# STM32F765BGT6 register map
File version: 1.0
Registers are 32-bit, access not given, reset 0x0 unless marked. A register's access mark holds for its fields unless they carry their own. Offsets are from the block's base; [hi:lo] are bit positions; {n}, {i} and the like mark numbered series.

## WWDG
Base 0x40002C00
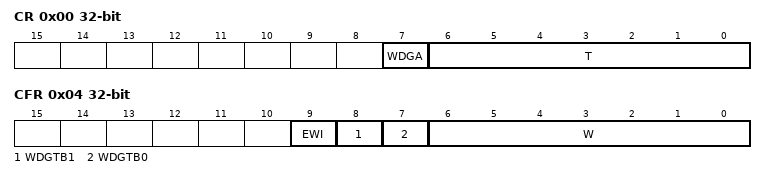
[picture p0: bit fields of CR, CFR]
0x00 CR
  [7] WDGA, [6:0] T
0x04 CFR
  [9] EWI, [8] WDGTB1, [7] WDGTB0, [6:0] W
0x08 SR
  [0] EWIF

## IWDG
Base 0x40003000
0x00 KR
  [15:0] KEY
0x04 PR
  [2:0] PR
0x08 RLR
  [11:0] RL
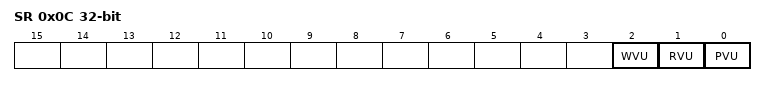
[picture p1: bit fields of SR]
0x0C SR
  [2] WVU, [1] RVU, [0] PVU
0x10 WINR
  [11:0] WIN

## CAN3
Base 0x40003400
Same registers: CAN1 0x40006400, CAN2 0x40006800
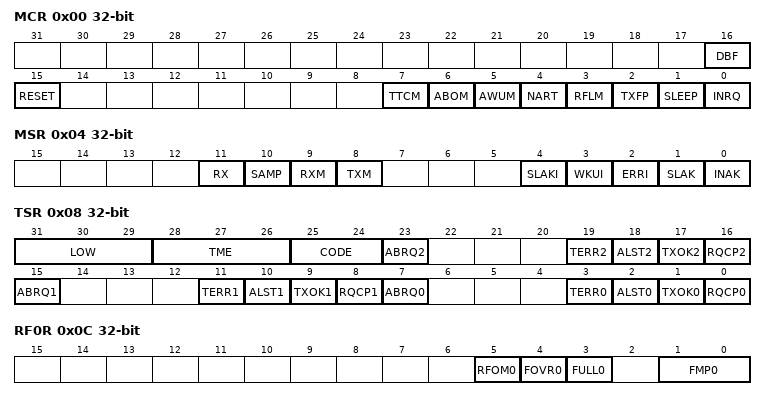
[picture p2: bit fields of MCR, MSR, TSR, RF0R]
0x00 MCR
  [16] DBF, [15] RESET, [7] TTCM, [6] ABOM, [5] AWUM, [4] NART, [3] RFLM, [2] TXFP, [1] SLEEP, [0] INRQ
0x04 MSR
  [11] RX, [10] SAMP, [9] RXM, [8] TXM, [4] SLAKI, [3] WKUI, [2] ERRI, [1] SLAK, [0] INAK
0x08 TSR
  [31:29] LOW, [28:26] TME, [25:24] CODE, [23] ABRQ2, [19] TERR2, [18] ALST2, [17] TXOK2, [16] RQCP2, [15] ABRQ1, [11] TERR1, [10] ALST1, [9] TXOK1, [8] RQCP1, [7] ABRQ0, [3] TERR0, [2] ALST0, [1] TXOK0, [0] RQCP0
0x0C RF0R
  [5] RFOM0, [4] FOVR0, [3] FULL0, [1:0] FMP0
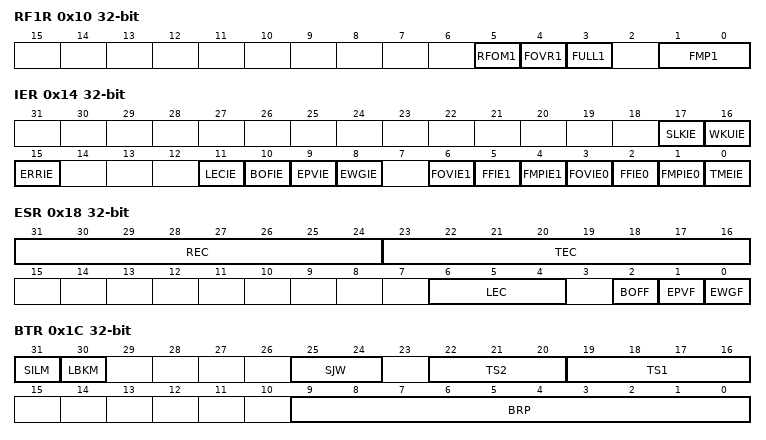
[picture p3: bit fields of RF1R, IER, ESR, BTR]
0x10 RF1R
  [5] RFOM1, [4] FOVR1, [3] FULL1, [1:0] FMP1
0x14 IER
  [17] SLKIE, [16] WKUIE, [15] ERRIE, [11] LECIE, [10] BOFIE, [9] EPVIE, [8] EWGIE, [6] FOVIE1, [5] FFIE1, [4] FMPIE1, [3] FOVIE0, [2] FFIE0, [1] FMPIE0, [0] TMEIE
0x18 ESR
  [31:24] REC, [23:16] TEC, [6:4] LEC, [2] BOFF, [1] EPVF, [0] EWGF
0x1C BTR
  [31] SILM, [30] LBKM, [25:24] SJW, [22:20] TS2, [19:16] TS1, [9:0] BRP
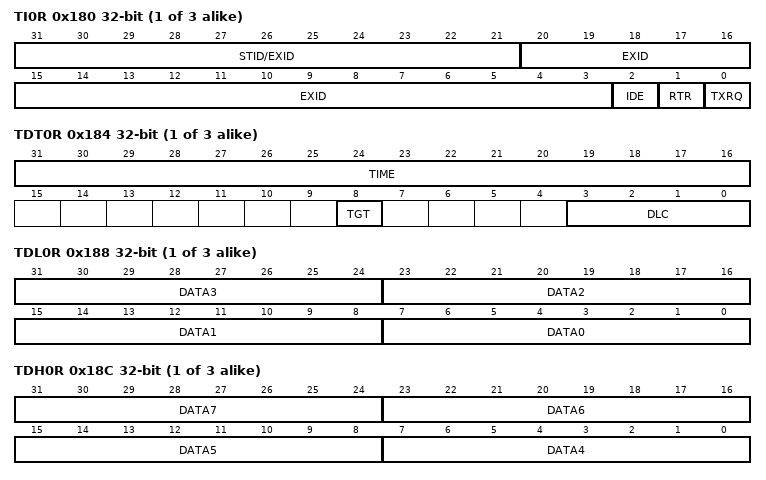
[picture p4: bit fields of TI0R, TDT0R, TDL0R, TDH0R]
{0x180+0x10*i} TI{i}R (i=0..2)
  [31:21] STID/EXID, [20:3] EXID, [2] IDE, [1] RTR, [0] TXRQ
{0x184+0x10*i} TDT{i}R (i=0..2)
  [31:16] TIME, [8] TGT, [3:0] DLC
{0x188+0x10*i} TDL{i}R (i=0..2)
  [8n+7:8n] DATA{n} (n=0..3)
{0x18C+0x10*i} TDH{i}R (i=0..2)
  [8n-25:8n-32] DATA{n} (n=4..7)
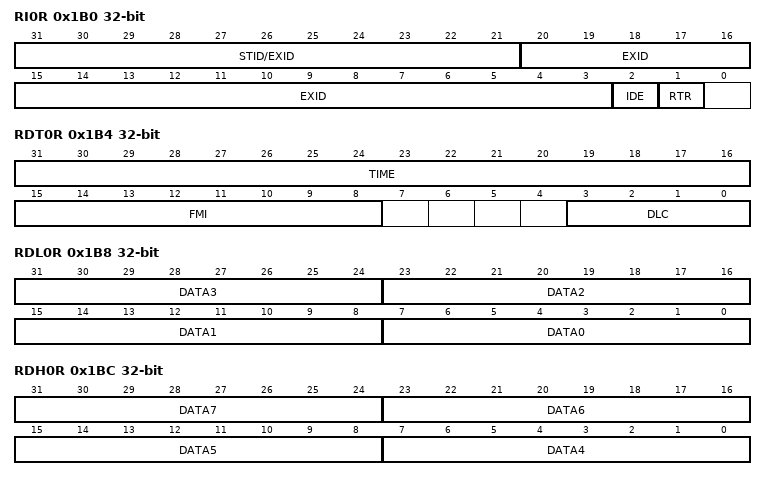
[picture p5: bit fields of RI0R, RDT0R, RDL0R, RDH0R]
0x1B0 RI0R
  [31:21] STID/EXID, [20:3] EXID, [2] IDE, [1] RTR
0x1B4 RDT0R
  [31:16] TIME, [15:8] FMI, [3:0] DLC
0x1B8 RDL0R
  [8n+7:8n] DATA{n} (n=0..3)
0x1BC RDH0R
  [8n-25:8n-32] DATA{n} (n=4..7)
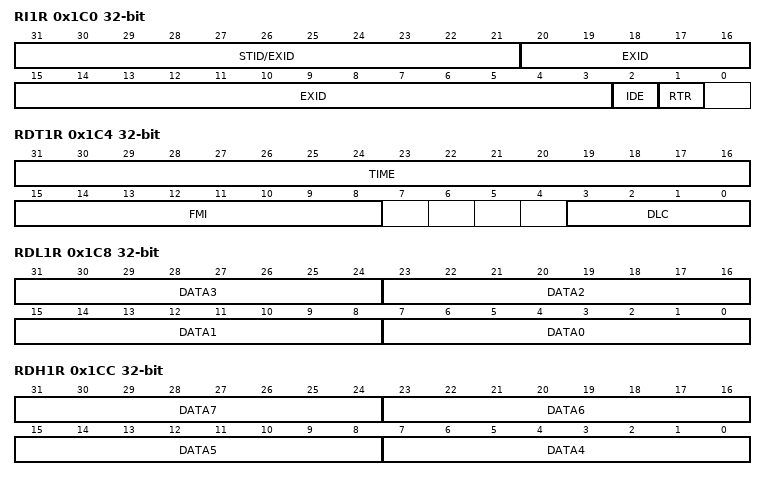
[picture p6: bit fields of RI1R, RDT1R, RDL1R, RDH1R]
0x1C0 RI1R
  [31:21] STID/EXID, [20:3] EXID, [2] IDE, [1] RTR
0x1C4 RDT1R
  [31:16] TIME, [15:8] FMI, [3:0] DLC
0x1C8 RDL1R
  [8n+7:8n] DATA{n} (n=0..3)
0x1CC RDH1R
  [8n-25:8n-32] DATA{n} (n=4..7)
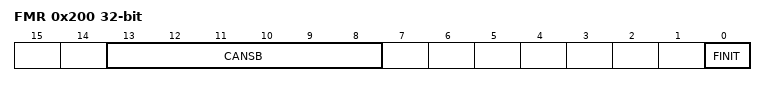
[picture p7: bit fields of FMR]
0x200 FMR
  [13:8] CANSB, [0] FINIT
0x204 FM1R
  [27:0] FBM
0x20C FS1R
  [27:0] FSC
0x214 FFA1R
  [27:0] FFA
0x21C FA1R
  [27:0] FACT
{0x240+8i} F{i}R1 (i=0..27)
  [31:0] FB
{0x244+8i} F{i}R2 (i=0..27)
  [31:0] FB

## SPI2
Base 0x40003800
Same registers: SPI3 0x40003C00, SPI1 0x40013000, SPI4 0x40013400, SPI5 0x40015000, SPI6 0x40015400
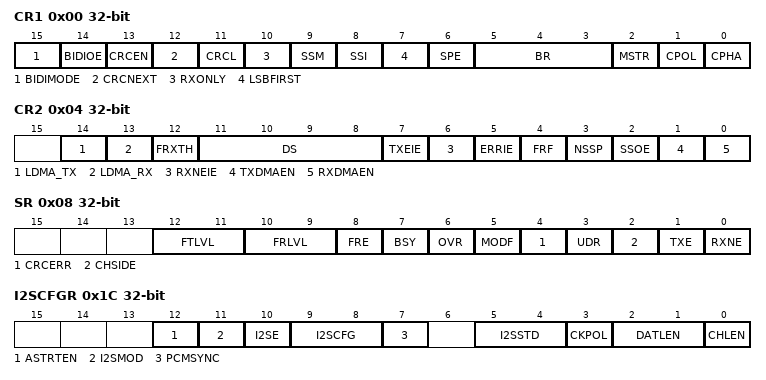
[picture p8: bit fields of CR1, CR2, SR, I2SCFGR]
0x00 CR1
  [15] BIDIMODE, [14] BIDIOE, [13] CRCEN, [12] CRCNEXT, [11] CRCL, [10] RXONLY, [9] SSM, [8] SSI, [7] LSBFIRST, [6] SPE, [5:3] BR, [2] MSTR, [1] CPOL, [0] CPHA
0x04 CR2
  [14] LDMA_TX, [13] LDMA_RX, [12] FRXTH, [11:8] DS, [7] TXEIE, [6] RXNEIE, [5] ERRIE, [4] FRF, [3] NSSP, [2] SSOE, [1] TXDMAEN, [0] RXDMAEN
0x08 SR
  [12:11] FTLVL, [10:9] FRLVL, [8] FRE, [7] BSY, [6] OVR, [5] MODF, [4] CRCERR, [3] UDR, [2] CHSIDE, [1] TXE, [0] RXNE
0x0C DR
  [15:0] DR
0x10 CRCPR
  [15:0] CRCPOLY
0x14 RXCRCR
  [15:0] RxCRC
0x18 TXCRCR
  [15:0] TxCRC
0x1C I2SCFGR
  [12] ASTRTEN, [11] I2SMOD, [10] I2SE, [9:8] I2SCFG, [7] PCMSYNC, [5:4] I2SSTD, [3] CKPOL, [2:1] DATLEN, [0] CHLEN
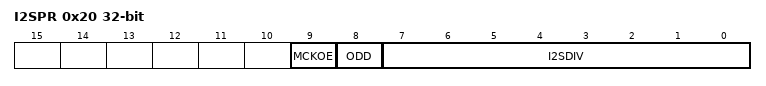
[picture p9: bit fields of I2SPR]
0x20 I2SPR
  [9] MCKOE, [8] ODD, [7:0] I2SDIV

## SPDIFRX
Base 0x40004000
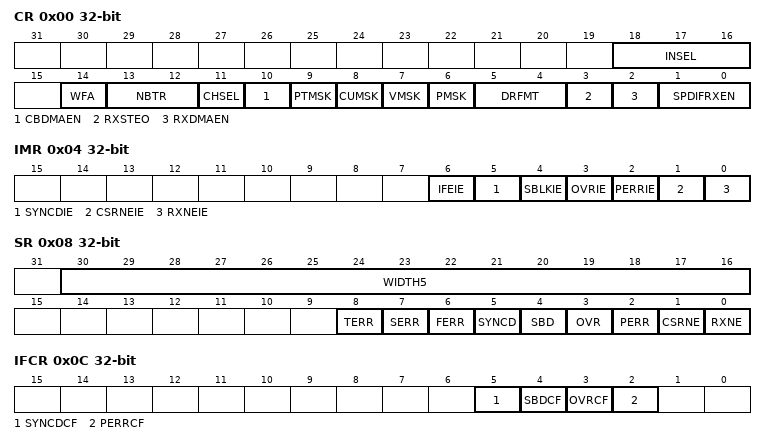
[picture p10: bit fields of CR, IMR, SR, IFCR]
0x00 CR
  [18:16] INSEL, [14] WFA, [13:12] NBTR, [11] CHSEL, [10] CBDMAEN, [9] PTMSK, [8] CUMSK, [7] VMSK, [6] PMSK, [5:4] DRFMT, [3] RXSTEO, [2] RXDMAEN, [1:0] SPDIFRXEN
0x04 IMR
  [6] IFEIE, [5] SYNCDIE, [4] SBLKIE, [3] OVRIE, [2] PERRIE, [1] CSRNEIE, [0] RXNEIE
0x08 SR
  [30:16] WIDTH5, [8] TERR, [7] SERR, [6] FERR, [5] SYNCD, [4] SBD, [3] OVR, [2] PERR, [1] CSRNE, [0] RXNE
0x0C IFCR
  [5] SYNCDCF, [4] SBDCF, [3] OVRCF, [2] PERRCF
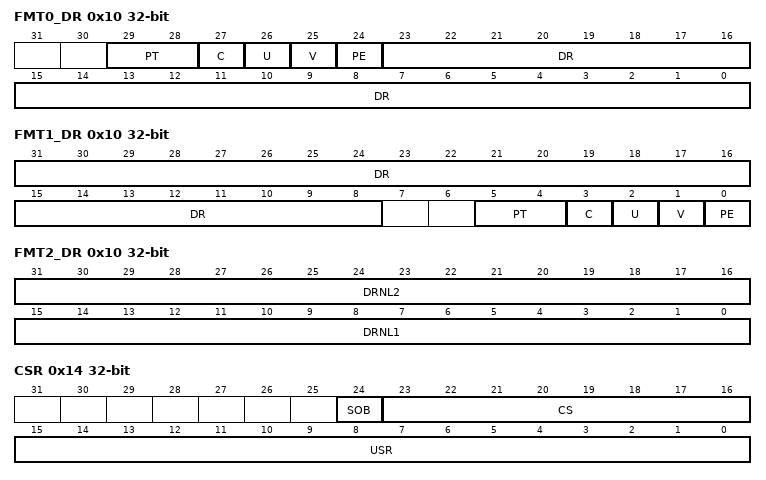
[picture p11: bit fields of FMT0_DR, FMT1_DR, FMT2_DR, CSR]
0x10 FMT0_DR
  [29:28] PT, [27] C, [26] U, [25] V, [24] PE, [23:0] DR
0x10 FMT1_DR
  [31:8] DR, [5:4] PT, [3] C, [2] U, [1] V, [0] PE
0x10 FMT2_DR
  [31:16] DRNL2, [15:0] DRNL1
0x14 CSR
  [24] SOB, [23:16] CS, [15:0] USR
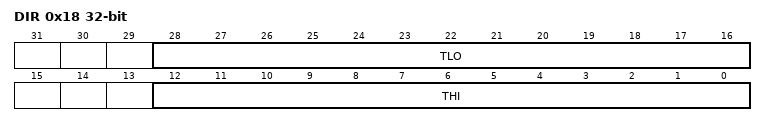
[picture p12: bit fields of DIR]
0x18 DIR
  [28:16] TLO, [12:0] THI
